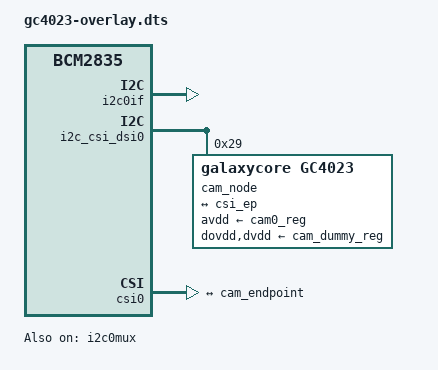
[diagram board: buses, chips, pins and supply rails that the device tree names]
/dts-v1/;
/plugin/;

/*
 * GC4023 on Raspberry Pi 5 CAM/DISP 0.
 * 2 lanes (table writes 0x0114 = 0x01). 27 MHz module crystal.
 * Link 351 MHz is the frequency the Rockchip driver publishes for this table.
 */

/{
	compatible = "brcm,bcm2835";

	fragment@0 {
		target = <&i2c0if>;
		__overlay__ {
			status = "okay";
		};
	};

	fragment@1 {
		target = <&i2c0mux>;
		__overlay__ {
			status = "okay";
		};
	};

	fragment@2 {
		target = <&cam0_clk>;
		__overlay__ {
			status = "okay";
			clock-frequency = <27000000>;
		};
	};

	fragment@3 {
		target = <&i2c_csi_dsi0>;
		__overlay__ {
			#address-cells = <1>;
			#size-cells = <0>;
			status = "okay";

			cam_node: gc4023@29 {
				compatible = "galaxycore,gc4023";
				reg = <0x29>;
				status = "okay";

				clocks = <&cam0_clk>;
				clock-names = "xclk";

				avdd-supply = <&cam0_reg>;
				dovdd-supply = <&cam_dummy_reg>;
				dvdd-supply = <&cam_dummy_reg>;

				rotation = <0>;
				orientation = <2>;

				port {
					cam_endpoint: endpoint {
						clock-lanes = <0>;
						data-lanes = <1 2>;
						link-frequencies =
							/bits/ 64 <351000000>;
						remote-endpoint = <&csi_ep>;
					};
				};
			};
		};
	};

	fragment@4 {
		target = <&csi0>;
		__overlay__ {
			status = "okay";

			port {
				csi_ep: endpoint {
					remote-endpoint = <&cam_endpoint>;
					clock-lanes = <0>;
					data-lanes = <1 2>;
				};
			};
		};
	};
};
